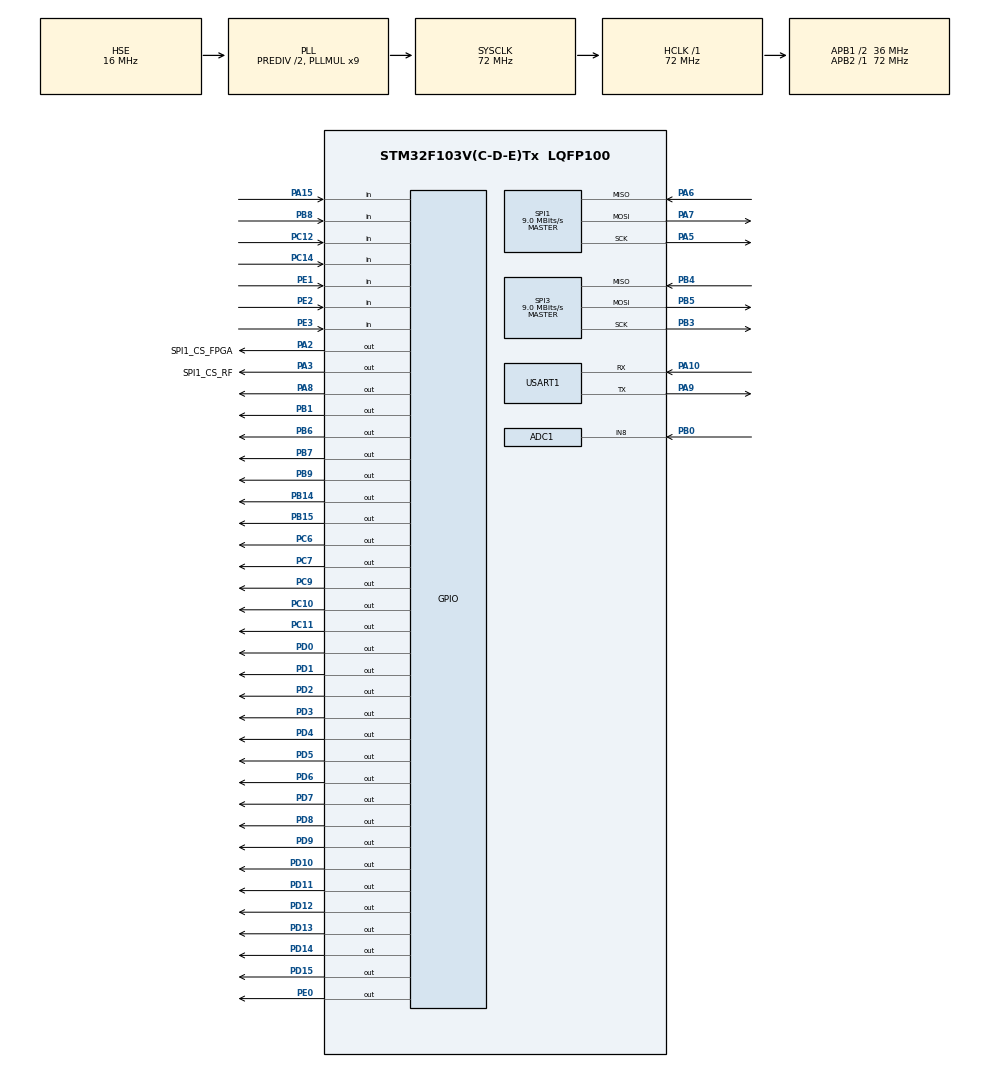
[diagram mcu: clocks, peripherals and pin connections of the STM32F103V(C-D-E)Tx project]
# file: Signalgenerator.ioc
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ADC1.Channel-0\#ChannelRegularConversion=ADC_CHANNEL_8
ADC1.Channel-1\#ChannelRegularConversion=ADC_CHANNEL_VREFINT
ADC1.NbrOfConversion=2
ADC1.NbrOfConversionFlag=1
ADC1.Rank-0\#ChannelRegularConversion=1
ADC1.Rank-1\#ChannelRegularConversion=2
ADC1.SamplingTime-0\#ChannelRegularConversion=ADC_SAMPLETIME_55CYCLES_5
ADC1.SamplingTime-1\#ChannelRegularConversion=ADC_SAMPLETIME_71CYCLES_5
ADC1.master=1
Dma.ADC1.0.Direction=DMA_PERIPH_TO_MEMORY
Dma.ADC1.0.Instance=DMA1_Channel1
Dma.ADC1.0.MemDataAlignment=DMA_MDATAALIGN_HALFWORD
Dma.ADC1.0.MemInc=DMA_MINC_ENABLE
Dma.ADC1.0.Mode=DMA_NORMAL
Dma.ADC1.0.PeriphDataAlignment=DMA_PDATAALIGN_HALFWORD
Dma.ADC1.0.PeriphInc=DMA_PINC_DISABLE
Dma.ADC1.0.Priority=DMA_PRIORITY_LOW
Dma.Request0=ADC1
Dma.Request1=SPI3_RX
Dma.Request2=SPI3_TX
Dma.Request3=SPI1_RX
Dma.Request4=SPI1_TX
Dma.SPI1_RX.3.Direction=DMA_PERIPH_TO_MEMORY
Dma.SPI1_RX.3.Instance=DMA1_Channel2
Dma.SPI1_RX.3.MemDataAlignment=DMA_MDATAALIGN_BYTE
Dma.SPI1_RX.3.MemInc=DMA_MINC_DISABLE
Dma.SPI1_RX.3.Mode=DMA_NORMAL
Dma.SPI1_RX.3.PeriphDataAlignment=DMA_PDATAALIGN_BYTE
Dma.SPI1_RX.3.PeriphInc=DMA_PINC_DISABLE
Dma.SPI1_RX.3.Priority=DMA_PRIORITY_LOW
Dma.SPI1_TX.4.Direction=DMA_MEMORY_TO_PERIPH
Dma.SPI1_TX.4.Instance=DMA1_Channel3
Dma.SPI1_TX.4.MemDataAlignment=DMA_MDATAALIGN_BYTE
Dma.SPI1_TX.4.MemInc=DMA_MINC_ENABLE
Dma.SPI1_TX.4.Mode=DMA_NORMAL
Dma.SPI1_TX.4.PeriphDataAlignment=DMA_PDATAALIGN_BYTE
Dma.SPI1_TX.4.PeriphInc=DMA_PINC_DISABLE
Dma.SPI1_TX.4.Priority=DMA_PRIORITY_LOW
Dma.SPI3_RX.1.Direction=DMA_PERIPH_TO_MEMORY
Dma.SPI3_RX.1.Instance=DMA2_Channel1
Dma.SPI3_RX.1.MemDataAlignment=DMA_MDATAALIGN_BYTE
Dma.SPI3_RX.1.MemInc=DMA_MINC_ENABLE
Dma.SPI3_RX.1.Mode=DMA_NORMAL
Dma.SPI3_RX.1.PeriphDataAlignment=DMA_PDATAALIGN_BYTE
Dma.SPI3_RX.1.PeriphInc=DMA_PINC_DISABLE
Dma.SPI3_RX.1.Priority=DMA_PRIORITY_LOW
Dma.SPI3_TX.2.Direction=DMA_MEMORY_TO_PERIPH
Dma.SPI3_TX.2.Instance=DMA2_Channel2
Dma.SPI3_TX.2.MemDataAlignment=DMA_MDATAALIGN_BYTE
Dma.SPI3_TX.2.MemInc=DMA_MINC_ENABLE
Dma.SPI3_TX.2.Mode=DMA_NORMAL
Dma.SPI3_TX.2.PeriphDataAlignment=DMA_PDATAALIGN_BYTE
Dma.SPI3_TX.2.PeriphInc=DMA_PINC_DISABLE
Dma.SPI3_TX.2.Priority=DMA_PRIORITY_LOW
FATFS._FS_RPATH=2
FATFS._LFN_UNICODE=0
FATFS._MAX_LFN=20
FATFS._USE_LFN=3
FREERTOS.MEMORY_ALLOCATION=2
FREERTOS.Tasks01=defaultTask,0,1000,StartDefaultTask,Default,NULL,Dynamic,NULL,NULL
FREERTOS.configCHECK_FOR_STACK_OVERFLOW=2
FREERTOS.configTOTAL_HEAP_SIZE=47000
FREERTOS.configUSE_PREEMPTION=0
FREERTOS.configUSE_TRACE_FACILITY=1
Mcu.Family=STM32F1
Mcu.Name=STM32F103V(C-D-E)Tx
Mcu.Package=LQFP100
NVIC.DMA1_Channel1_IRQn=true\:5\:0\:false\:false\:true\:true\:true\:true
NVIC.DMA1_Channel2_IRQn=true\:5\:0\:false\:false\:true\:true\:false\:true
NVIC.DMA1_Channel3_IRQn=true\:5\:0\:false\:false\:true\:true\:false\:true
NVIC.DMA2_Channel1_IRQn=true\:5\:0\:false\:false\:true\:true\:false\:true
NVIC.DMA2_Channel2_IRQn=true\:5\:0\:false\:false\:true\:true\:false\:true
NVIC.PriorityGroup=NVIC_PRIORITYGROUP_4
NVIC.TIM2_IRQn=true\:0\:0\:false\:false\:true\:false\:true\:true
NVIC.TIM3_IRQn=true\:5\:0\:false\:false\:true\:true\:true\:true
NVIC.TimeBase=TIM2_IRQn
NVIC.TimeBaseIP=TIM2
OSC_IN.Mode=HSE-External-Oscillator
OSC_IN.Signal=RCC_OSC_IN
OSC_OUT.Mode=HSE-External-Oscillator
OSC_OUT.Signal=RCC_OSC_OUT
PA10.Mode=Asynchronous
PA10.Signal=USART1_RX
PA13.Mode=Serial_Wire
PA13.Signal=SYS_JTMS-SWDIO
PA14.Mode=Serial_Wire
PA14.Signal=SYS_JTCK-SWCLK
PA15.GPIO_PuPd=GPIO_PULLUP
PA15.Signal=GPIO_Input
PA2.GPIO_Label=SPI1_CS_FPGA
PA2.GPIO_Speed=GPIO_SPEED_FREQ_HIGH
PA2.PinState=GPIO_PIN_SET
PA2.Signal=GPIO_Output
PA3.GPIO_Label=SPI1_CS_RF
PA3.GPIO_Speed=GPIO_SPEED_FREQ_HIGH
PA3.PinState=GPIO_PIN_SET
PA3.Signal=GPIO_Output
PA5.Mode=Full_Duplex_Master
PA5.Signal=SPI1_SCK
PA6.GPIO_PuPd=GPIO_PULLDOWN
PA6.Mode=Full_Duplex_Master
PA6.Signal=SPI1_MISO
PA7.Mode=Full_Duplex_Master
PA7.Signal=SPI1_MOSI
PA8.Signal=GPIO_Output
PA9.Mode=Asynchronous
PA9.Signal=USART1_TX
PB0.Signal=ADCx_IN8
PB1.Signal=GPIO_Output
PB14.GPIO_Speed=GPIO_SPEED_FREQ_HIGH
PB14.Signal=GPIO_Output
PB15.GPIO_Speed=GPIO_SPEED_FREQ_HIGH
PB15.Signal=GPIO_Output
PB3.Mode=Full_Duplex_Master
PB3.Signal=SPI3_SCK
PB4.GPIO_PuPd=GPIO_PULLUP
PB4.Mode=Full_Duplex_Master
PB4.Signal=SPI3_MISO
PB5.Mode=Full_Duplex_Master
PB5.Signal=SPI3_MOSI
PB6.GPIO_Speed=GPIO_SPEED_FREQ_HIGH
PB6.PinState=GPIO_PIN_SET
PB6.Signal=GPIO_Output
PB7.GPIO_Speed=GPIO_SPEED_FREQ_HIGH
PB7.PinState=GPIO_PIN_SET
PB7.Signal=GPIO_Output
PB8.GPIO_PuPd=GPIO_PULLUP
PB8.Signal=GPIO_Input
PB9.GPIO_Speed=GPIO_SPEED_FREQ_HIGH
PB9.Signal=GPIO_Output
PC10.Signal=GPIO_Output
PC11.Signal=GPIO_Output
PC12.GPIO_PuPd=GPIO_PULLUP
PC12.Signal=GPIO_Input
PC14-OSC32_IN.GPIO_PuPd=GPIO_PULLUP
PC14-OSC32_IN.Signal=GPIO_Input
PC6.GPIO_Speed=GPIO_SPEED_FREQ_HIGH
PC6.Signal=GPIO_Output
PC7.Signal=GPIO_Output
PC9.Signal=GPIO_Output
PD0.GPIO_Speed=GPIO_SPEED_FREQ_HIGH
PD0.PinState=GPIO_PIN_RESET
PD0.Signal=GPIO_Output
PD1.GPIO_Speed=GPIO_SPEED_FREQ_HIGH
PD1.Signal=GPIO_Output
PD10.GPIO_Speed=GPIO_SPEED_FREQ_HIGH
PD10.Signal=GPIO_Output
PD11.GPIO_Speed=GPIO_SPEED_FREQ_HIGH
PD11.Signal=GPIO_Output
PD12.GPIO_Speed=GPIO_SPEED_FREQ_HIGH
PD12.Signal=GPIO_Output
PD13.GPIO_Speed=GPIO_SPEED_FREQ_HIGH
PD13.Signal=GPIO_Output
PD14.GPIO_Speed=GPIO_SPEED_FREQ_HIGH
PD14.Signal=GPIO_Output
PD15.GPIO_Speed=GPIO_SPEED_FREQ_HIGH
PD15.Signal=GPIO_Output
PD2.GPIO_Speed=GPIO_SPEED_FREQ_HIGH
PD2.Signal=GPIO_Output
PD3.GPIO_Speed=GPIO_SPEED_FREQ_HIGH
PD3.Signal=GPIO_Output
PD4.GPIO_Speed=GPIO_SPEED_FREQ_HIGH
PD4.Signal=GPIO_Output
PD5.GPIO_Speed=GPIO_SPEED_FREQ_HIGH
PD5.Signal=GPIO_Output
PD6.GPIO_Speed=GPIO_SPEED_FREQ_HIGH
PD6.Signal=GPIO_Output
PD7.GPIO_Speed=GPIO_SPEED_FREQ_HIGH
PD7.Signal=GPIO_Output
PD8.GPIO_Speed=GPIO_SPEED_FREQ_HIGH
PD8.Signal=GPIO_Output
PD9.GPIO_Speed=GPIO_SPEED_FREQ_HIGH
PD9.Signal=GPIO_Output
PE0.GPIO_Speed=GPIO_SPEED_FREQ_HIGH
PE0.Signal=GPIO_Output
PE1.GPIO_PuPd=GPIO_PULLUP
PE1.Signal=GPIO_Input
PE2.GPIO_PuPd=GPIO_PULLUP
PE2.Signal=GPIO_Input
PE3.GPIO_PuPd=GPIO_PULLUP
PE3.Signal=GPIO_Input
ProjectManager.HeapSize=0x200
ProjectManager.StackSize=0x400
ProjectManager.TargetToolchain=SW4STM32
RCC.ADCPresc=RCC_ADCPCLK2_DIV6
RCC.AHBFreq_Value=72000000
RCC.APB1CLKDivider=RCC_HCLK_DIV2
RCC.APB1Freq_Value=36000000
RCC.APB1TimFreq_Value=72000000
RCC.APB2Freq_Value=72000000
RCC.APB2TimFreq_Value=72000000
RCC.HCLKFreq_Value=72000000
RCC.HSEDivPLL=RCC_HSE_PREDIV_DIV2
RCC.HSE_VALUE=16000000
RCC.PLLMUL=RCC_PLL_MUL9
RCC.PLLSourceVirtual=RCC_PLLSOURCE_HSE
RCC.SYSCLKFreq_VALUE=72000000
RCC.SYSCLKSource=RCC_SYSCLKSOURCE_PLLCLK
RCC.USBFreq_Value=48000000
RCC.USBPrescaler=RCC_USBCLKSOURCE_PLL_DIV1_5
SH.ADCx_IN8.0=ADC1_IN8,IN8
SPI1.BaudRatePrescaler=SPI_BAUDRATEPRESCALER_8
SPI1.CRCCalculation=SPI_CRCCALCULATION_DISABLE
SPI1.CalculateBaudRate=9.0 MBits/s
SPI1.DataSize=SPI_DATASIZE_8BIT
SPI1.Direction=SPI_DIRECTION_2LINES
SPI1.Mode=SPI_MODE_MASTER
SPI1.VirtualType=VM_MASTER
SPI3.BaudRatePrescaler=SPI_BAUDRATEPRESCALER_4
SPI3.CalculateBaudRate=9.0 MBits/s
SPI3.Direction=SPI_DIRECTION_2LINES
SPI3.Mode=SPI_MODE_MASTER
SPI3.VirtualType=VM_MASTER
TIM3.Period=999
TIM3.Prescaler=71
USART1.VirtualMode=VM_ASYNC
VP_ADC1_Vref_Input.Mode=IN-Vrefint
VP_FATFS_VS_Generic.Mode=User_defined
VP_FREERTOS_VS_CMSIS_V1.Mode=CMSIS_V1
VP_SYS_VS_tim2.Mode=TIM2
VP_TIM3_VS_ClockSourceINT.Mode=Internal
board=Signalgenerator

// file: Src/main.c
/* USER CODE BEGIN Header */
/**
  ******************************************************************************
  * @file           : main.c
  * @brief          : Main program body
  ******************************************************************************
  * @attention
  *
  * <h2><center>&copy; Copyright (c) 2019 STMicroelectronics.
  * All rights reserved.</center></h2>
  *
  * This software component is licensed by ST under Ultimate Liberty license
  * SLA0044, the "License"; You may not use this file except in compliance with
  * the License. You may obtain a copy of the License at:
  *                             www.st.com/SLA0044
  *
  ******************************************************************************
  */
/* USER CODE END Header */

#include "main.h"
#include "cmsis_os.h"
#include "adc.h"
#include "dma.h"
#include "fatfs.h"
#include "spi.h"
#include "tim.h"
#include "usart.h"
#include "gpio.h"

/* USER CODE BEGIN PV */
/* Private variables ---------------------------------------------------------*/

/* USER CODE END PV */

void SystemClock_Config(void);
void MX_FREERTOS_Init(void);
/* USER CODE BEGIN PFP */
/* Private function prototypes -----------------------------------------------*/

/* USER CODE END PFP */

int main(void)
{

  /* MCU Configuration--------------------------------------------------------*/

  /* Reset of all peripherals, Initializes the Flash interface and the Systick. */
  HAL_Init();

  /* Configure the system clock */
  SystemClock_Config();

  /* Initialize all configured peripherals */
  MX_GPIO_Init();
  MX_DMA_Init();
  MX_ADC1_Init();
  MX_SPI1_Init();
  MX_SPI3_Init();
  MX_USART1_UART_Init();
  MX_TIM3_Init();
  /* USER CODE BEGIN 2 */
  HAL_TIM_Base_Start_IT(&htim3);
  display_Init();
  /* USER CODE END 2 */

  /* Call init function for freertos objects (in freertos.c) */
  MX_FREERTOS_Init();

  /* Start scheduler */
  osKernelStart();

  /* We should never get here as control is now taken by the scheduler */

  /* Infinite loop */
  while (1)
  {

  }
}

void SystemClock_Config(void)
{
  RCC_OscInitTypeDef RCC_OscInitStruct = {0};
  RCC_ClkInitTypeDef RCC_ClkInitStruct = {0};
  RCC_PeriphCLKInitTypeDef PeriphClkInit = {0};

  /** Initializes the CPU, AHB and APB busses clocks
  */
  RCC_OscInitStruct.OscillatorType = RCC_OSCILLATORTYPE_HSE;
  RCC_OscInitStruct.HSEState = RCC_HSE_ON;
  RCC_OscInitStruct.HSEPredivValue = RCC_HSE_PREDIV_DIV2;
  RCC_OscInitStruct.HSIState = RCC_HSI_ON;
  RCC_OscInitStruct.PLL.PLLState = RCC_PLL_ON;
  RCC_OscInitStruct.PLL.PLLSource = RCC_PLLSOURCE_HSE;
  RCC_OscInitStruct.PLL.PLLMUL = RCC_PLL_MUL9;
  if (HAL_RCC_OscConfig(&RCC_OscInitStruct) != HAL_OK)
  {
    Error_Handler();
  }
  /** Initializes the CPU, AHB and APB busses clocks
  */
  RCC_ClkInitStruct.ClockType = RCC_CLOCKTYPE_HCLK|RCC_CLOCKTYPE_SYSCLK
                              |RCC_CLOCKTYPE_PCLK1|RCC_CLOCKTYPE_PCLK2;
  RCC_ClkInitStruct.SYSCLKSource = RCC_SYSCLKSOURCE_PLLCLK;
  RCC_ClkInitStruct.AHBCLKDivider = RCC_SYSCLK_DIV1;
  RCC_ClkInitStruct.APB1CLKDivider = RCC_HCLK_DIV2;
  RCC_ClkInitStruct.APB2CLKDivider = RCC_HCLK_DIV1;

  if (HAL_RCC_ClockConfig(&RCC_ClkInitStruct, FLASH_LATENCY_2) != HAL_OK)
  {
    Error_Handler();
  }
  PeriphClkInit.PeriphClockSelection = RCC_PERIPHCLK_ADC;
  PeriphClkInit.AdcClockSelection = RCC_ADCPCLK2_DIV6;
  if (HAL_RCCEx_PeriphCLKConfig(&PeriphClkInit) != HAL_OK)
  {
    Error_Handler();
  }
}

void HAL_TIM_PeriodElapsedCallback(TIM_HandleTypeDef *htim)
{
  if (htim->Instance == TIM2) {
    HAL_IncTick();
  }
}

void Error_Handler(void)
{
  while(1)
  {
  }
}

/************************ (C) COPYRIGHT STMicroelectronics *****END OF FILE****/

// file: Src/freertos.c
/* USER CODE BEGIN Header */
/**
  ******************************************************************************
  * File Name          : freertos.c
  * Description        : Code for freertos applications
  ******************************************************************************
  * @attention
  *
  * <h2><center>&copy; Copyright (c) 2019 STMicroelectronics.
  * All rights reserved.</center></h2>
  *
  * This software component is licensed by ST under Ultimate Liberty license
  * SLA0044, the "License"; You may not use this file except in compliance with
  * the License. You may obtain a copy of the License at:
  *                             www.st.com/SLA0044
  *
  ******************************************************************************
  */
/* USER CODE END Header */

#include "FreeRTOS.h"
#include "task.h"
#include "main.h"
#include "cmsis_os.h"

/* USER CODE BEGIN Includes */
#include "startup.h"
/* USER CODE END Includes */

/* USER CODE BEGIN Variables */
SemaphoreHandle_t xMutexSPI3;
/* USER CODE END Variables */
osThreadId defaultTaskHandle;

void StartDefaultTask(void const * argument);

extern void MX_FATFS_Init(void);
void MX_FREERTOS_Init(void); /* (MISRA C 2004 rule 8.1) */

/* GetIdleTaskMemory prototype (linked to static allocation support) */
void vApplicationGetIdleTaskMemory( StaticTask_t **ppxIdleTaskTCBBuffer, StackType_t **ppxIdleTaskStackBuffer, uint32_t *pulIdleTaskStackSize );

/* Hook prototypes */
void vApplicationStackOverflowHook(xTaskHandle xTask, signed char *pcTaskName);

/* USER CODE BEGIN 4 */
__weak void vApplicationStackOverflowHook(xTaskHandle xTask, signed char *pcTaskName)
{
   /* Run time stack overflow checking is performed if
   configCHECK_FOR_STACK_OVERFLOW is defined to 1 or 2. This hook function is
   called if a stack overflow is detected. */
}
/* USER CODE END 4 */

/* USER CODE BEGIN GET_IDLE_TASK_MEMORY */
static StaticTask_t xIdleTaskTCBBuffer;
static StackType_t xIdleStack[configMINIMAL_STACK_SIZE];

void vApplicationGetIdleTaskMemory( StaticTask_t **ppxIdleTaskTCBBuffer, StackType_t **ppxIdleTaskStackBuffer, uint32_t *pulIdleTaskStackSize )
{
  *ppxIdleTaskTCBBuffer = &xIdleTaskTCBBuffer;
  *ppxIdleTaskStackBuffer = &xIdleStack[0];
  *pulIdleTaskStackSize = configMINIMAL_STACK_SIZE;
  /* place for user code */
}
/* USER CODE END GET_IDLE_TASK_MEMORY */

void MX_FREERTOS_Init(void) {

  /* USER CODE BEGIN RTOS_MUTEX */
  /* add mutexes, ... */
	xMutexSPI3 = xSemaphoreCreateMutex();
  /* USER CODE END RTOS_MUTEX */

  /* Create the thread(s) */
  /* definition and creation of defaultTask */
  osThreadDef(defaultTask, StartDefaultTask, osPriorityNormal, 0, 1000);
  defaultTaskHandle = osThreadCreate(osThread(defaultTask), NULL);

}

void StartDefaultTask(void const * argument)
{
  /* init code for FATFS */
  MX_FATFS_Init();

  /* USER CODE BEGIN StartDefaultTask */
  startup_Hardware();

  startup_Software();
  /* Infinite loop */
  for(;;)
  {
    osDelay(1);
  }
  /* USER CODE END StartDefaultTask */
}

/************************ (C) COPYRIGHT STMicroelectronics *****END OF FILE****/
